# HDSC_HC32F4A0 register map
Vendor: HDSC Co.,Ltd.; Series: ARMCM4; File version: 1.0
CPU: CM4 r0p1, little endian, MPU, FPU, 4 interrupt priority bits
Registers are 32-bit, read-write, reset 0x0 unless marked. A register's access mark holds for its fields unless they carry their own. Offsets are from the block's base; [hi:lo] are bit positions; {n}, {i} and the like mark numbered series.

## SMC
Base 0x88000000
0x00 STSR ro reset 0x1
  [0] STATUS
0x08 STCR0 wo
  [2] LPWIR
0x0C STCR1 wo
  [2] LPWOR
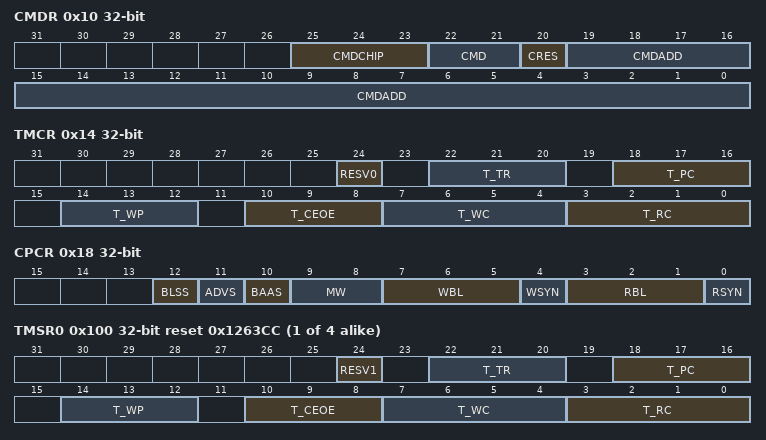
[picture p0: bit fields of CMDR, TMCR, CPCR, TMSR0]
0x10 CMDR wo
  [25:23] CMDCHIP, [22:21] CMD, [20] CRES, [19:0] CMDADD
0x14 TMCR wo
  [24] RESV0 rw, [22:20] T_TR, [18:16] T_PC, [14:12] T_WP, [10:8] T_CEOE, [7:4] T_WC, [3:0] T_RC
0x18 CPCR wo
  [12] BLSS, [11] ADVS, [10] BAAS, [9:8] MW, [7:5] WBL, [4] WSYN, [3:1] RBL, [0] RSYN
0x20 RFTR
  [3:0] REFPRD
{0x100+0x20*i} TMSR{i} ro reset 0x1263CC (i=0..3)
  [24] RESV1 rw, [22:20] T_TR, [18:16] T_PC, [14:12] T_WP, [10:8] T_CEOE, [7:4] T_WC, [3:0] T_RC
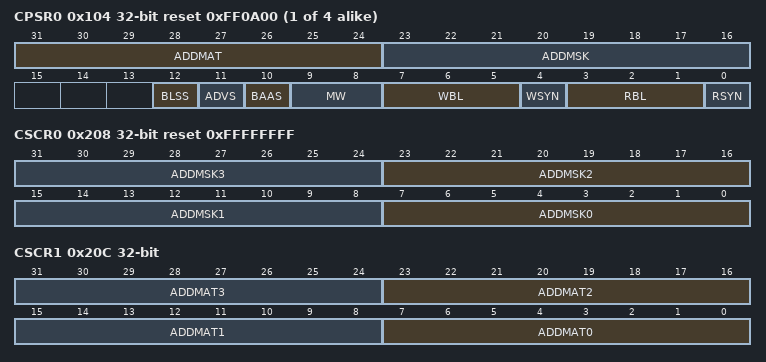
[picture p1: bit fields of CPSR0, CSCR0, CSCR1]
{0x104+0x20*i} CPSR{i} ro reset 0xFF0A00 (i=0..3)
  [31:24] ADDMAT, [23:16] ADDMSK, [12] BLSS, [11] ADVS, [10] BAAS, [9:8] MW, [7:5] WBL, [4] WSYN, [3:1] RBL, [0] RSYN
0x200 BACR reset 0x300
  [4] MUXMD
0x208 CSCR0 reset 0xFFFFFFFF
  [8n+7:8n] ADDMSK{n} (n=0..3)
0x20C CSCR1
  [8n+7:8n] ADDMAT{n} (n=0..3)

## SPI1
Base 0x4001C000
Same registers: SPI2 0x4001C400, SPI3 0x4001C800, SPI4 0x40020000, SPI5 0x40020400, SPI6 0x40020800
0x00 DR
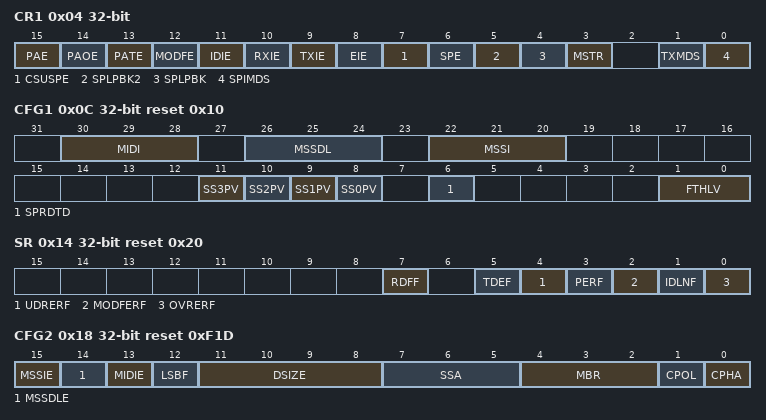
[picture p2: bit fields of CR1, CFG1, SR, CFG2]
0x04 CR1
  [15] PAE, [14] PAOE, [13] PATE, [12] MODFE, [11] IDIE, [10] RXIE, [9] TXIE, [8] EIE, [7] CSUSPE, [6] SPE, [5] SPLPBK2, [4] SPLPBK, [3] MSTR, [1] TXMDS, [0] SPIMDS
0x0C CFG1 reset 0x10
  [30:28] MIDI, [26:24] MSSDL, [22:20] MSSI, [n+8] SS{n}PV (n=0..3), [6] SPRDTD, [1:0] FTHLV
0x14 SR reset 0x20
  [7] RDFF, [5] TDEF, [4] UDRERF, [3] PERF, [2] MODFERF, [1] IDLNF, [0] OVRERF
0x18 CFG2 reset 0xF1D
  [15] MSSIE, [14] MSSDLE, [13] MIDIE, [12] LSBF, [11:8] DSIZE, [7:5] SSA, [4:2] MBR, [1] CPOL, [0] CPHA

## SRAMC
Base 0x40050800
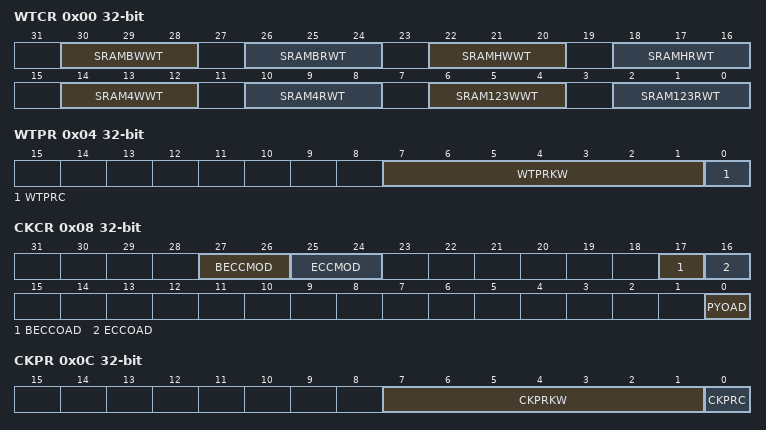
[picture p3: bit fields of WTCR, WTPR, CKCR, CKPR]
0x00 WTCR
  [30:28] SRAMBWWT, [26:24] SRAMBRWT, [22:20] SRAMHWWT, [18:16] SRAMHRWT, [14:12] SRAM4WWT, [10:8] SRAM4RWT, [6:4] SRAM123WWT, [2:0] SRAM123RWT
0x04 WTPR
  [7:1] WTPRKW, [0] WTPRC
0x08 CKCR
  [27:26] BECCMOD, [25:24] ECCMOD, [17] BECCOAD, [16] ECCOAD, [0] PYOAD
0x0C CKPR
  [7:1] CKPRKW, [0] CKPRC
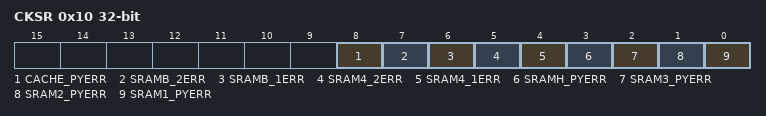
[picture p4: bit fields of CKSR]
0x10 CKSR
  [8] CACHE_PYERR, [7] SRAMB_2ERR, [6] SRAMB_1ERR, [5] SRAM4_2ERR, [4] SRAM4_1ERR, [3] SRAMH_PYERR, [2] SRAM3_PYERR, [1] SRAM2_PYERR, [0] SRAM1_PYERR

## SWDT
Base 0x40049400
Same registers: WDT 0x40049000
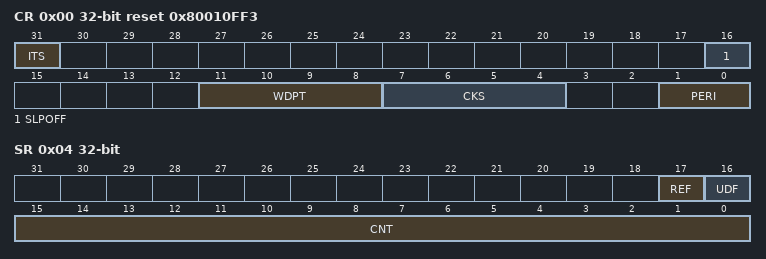
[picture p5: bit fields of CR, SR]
0x00 CR reset 0x80010FF3
  [31] ITS, [16] SLPOFF, [11:8] WDPT, [7:4] CKS, [1:0] PERI
0x04 SR ro
  [17] REF rw, [16] UDF rw, [15:0] CNT
0x08 RR ro
  [15:0] RF

## TMR01
Base 0x40024000
Same registers: TMR02 0x40024400
0x00 CNTAR
  [15:0] CNTA
0x04 CNTBR
  [15:0] CNTB
0x08 CMPAR reset 0xFFFF
  [15:0] CMPA
0x0C CMPBR reset 0xFFFF
  [15:0] CMPB
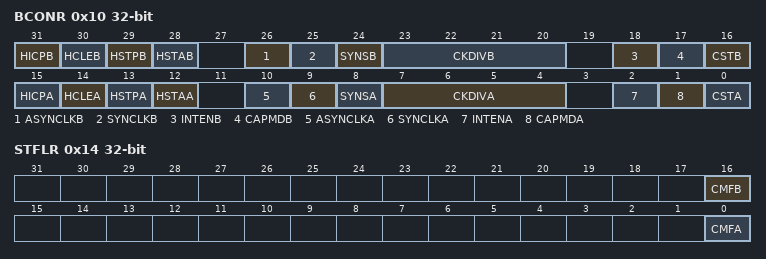
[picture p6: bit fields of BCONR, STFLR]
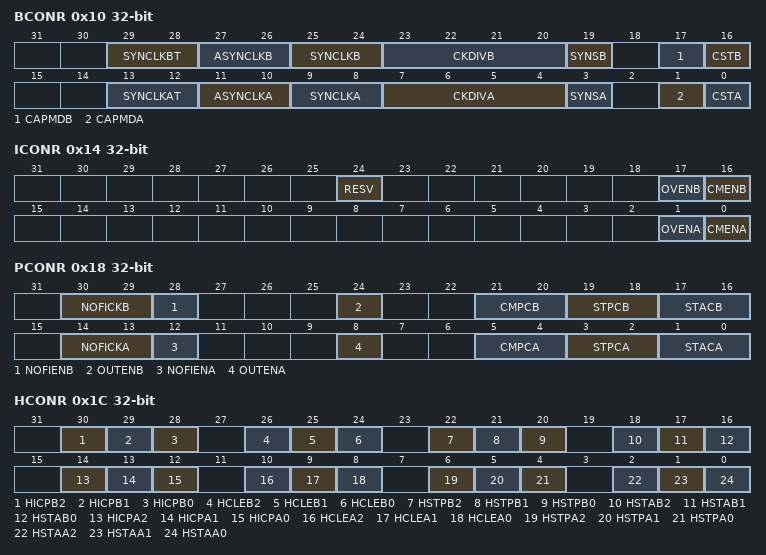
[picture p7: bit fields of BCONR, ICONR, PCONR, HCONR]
0x10 BCONR
  [31] HICPB, [30] HCLEB, [29] HSTPB, [28] HSTAB, [26] ASYNCLKB, [25] SYNCLKB, [24] SYNSB, [23:20] CKDIVB, [18] INTENB, [17] CAPMDB, [16] CSTB, [15] HICPA, [14] HCLEA, [13] HSTPA, [12] HSTAA, [10] ASYNCLKA, [9] SYNCLKA, [8] SYNSA, [7:4] CKDIVA, [2] INTENA, [1] CAPMDA, [0] CSTA
0x14 STFLR
  [16] CMFB, [0] CMFA

## TMR21
Base 0x40024800
Same registers: TMR22 0x40024C00, TMR23 0x40025000, TMR24 0x40025400
0x00 CNTAR
  [15:0] CNTA
0x04 CNTBR
  [15:0] CNTB
0x08 CMPAR reset 0xFFFF
  [15:0] CMPA
0x0C CMPBR reset 0xFFFF
  [15:0] CMPB
0x10 BCONR
  [29:28] SYNCLKBT, [27:26] ASYNCLKB, [25:24] SYNCLKB, [23:20] CKDIVB, [19] SYNSB, [17] CAPMDB, [16] CSTB, [13:12] SYNCLKAT, [11:10] ASYNCLKA, [9:8] SYNCLKA, [7:4] CKDIVA, [3] SYNSA, [1] CAPMDA, [0] CSTA
0x14 ICONR
  [24] RESV, [17] OVENB, [16] CMENB, [1] OVENA, [0] CMENA
0x18 PCONR
  [30:29] NOFICKB, [28] NOFIENB, [24] OUTENB, [21:20] CMPCB, [19:18] STPCB, [17:16] STACB, [14:13] NOFICKA, [12] NOFIENA, [8] OUTENA, [5:4] CMPCA, [3:2] STPCA, [1:0] STACA
0x1C HCONR
  [30] HICPB2, [29] HICPB1, [28] HICPB0, [26] HCLEB2, [25] HCLEB1, [24] HCLEB0, [22] HSTPB2, [21] HSTPB1, [20] HSTPB0, [18] HSTAB2, [17] HSTAB1, [16] HSTAB0, [14] HICPA2, [13] HICPA1, [12] HICPA0, [10] HCLEA2, [9] HCLEA1, [8] HCLEA0, [6] HSTPA2, [5] HSTPA1, [4] HSTPA0, [2] HSTAA2, [1] HSTAA1, [0] HSTAA0
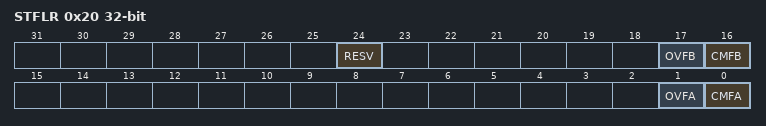
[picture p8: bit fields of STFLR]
0x20 STFLR
  [24] RESV, [17] OVFB, [16] CMFB, [1] OVFA, [0] CMFA
